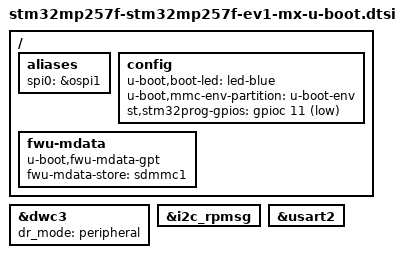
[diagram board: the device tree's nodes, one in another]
#include "stm32mp25-u-boot.dtsi"

/* USER CODE BEGIN includes */
/* USER CODE END includes */

/{

	/* USER CODE BEGIN root */

	aliases{
		spi0 = &ospi1;
	};

	config{
		u-boot,boot-led = "led-blue";
		u-boot,mmc-env-partition = "u-boot-env";
		st,stm32prog-gpios = <&gpioc 11 (GPIO_ACTIVE_LOW | GPIO_PULL_UP)>;
	};

	fwu-mdata{
		compatible = "u-boot,fwu-mdata-gpt";
		fwu-mdata-store = <&sdmmc1>;
	};
	/* USER CODE END root */
};

/* USER CODE BEGIN addons */

&dwc3{
	dr_mode = "peripheral";
	/delete-node/ port;
};

&i2c_rpmsg{
	/delete-node/ typec@35;
};

&usart2{
	bootph-all;
};
/* USER CODE END addons */
